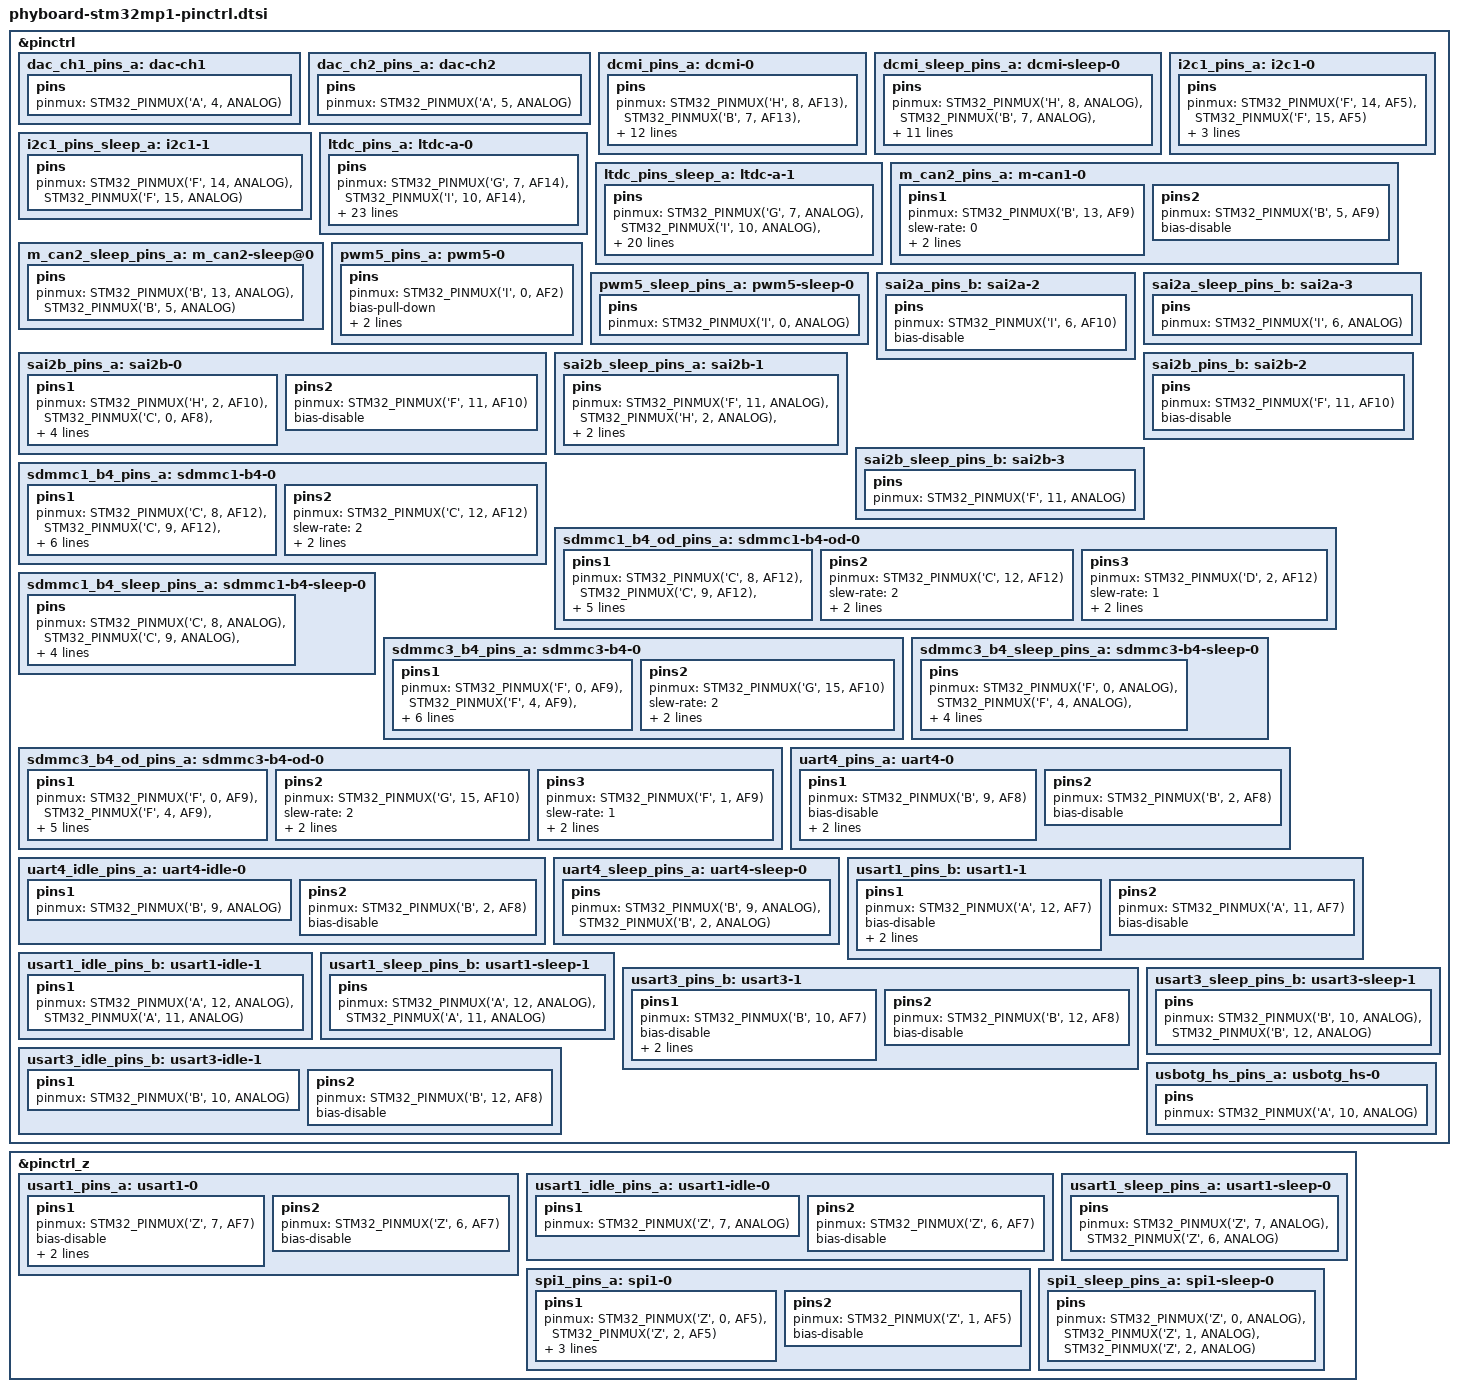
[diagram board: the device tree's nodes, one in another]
// SPDX-License-Identifier: (GPL-2.0+ OR BSD-3-Clause)
/*
 * Copyright (C) PHYTEC GmbH 2019-2020 - All Rights Reserved
 * Author: Dom VOVARD <dom.vovard@linrt.com>.
 */

#include <dt-bindings/pinctrl/stm32-pinfunc.h>

&pinctrl {

			dac_ch1_pins_a: dac-ch1 {
				pins {
					pinmux = <STM32_PINMUX('A', 4, ANALOG)>;
				};
			};

			dac_ch2_pins_a: dac-ch2 {
				pins {
					pinmux = <STM32_PINMUX('A', 5, ANALOG)>;
				};
			};

			dcmi_pins_a: dcmi-0 {
				pins {
					pinmux = <STM32_PINMUX('H', 8,  AF13)>,/* DCMI_HSYNC */
						 <STM32_PINMUX('B', 7,  AF13)>,/* DCMI_VSYNC */
						 <STM32_PINMUX('A', 6,  AF13)>,/* DCMI_PIXCLK */
						 <STM32_PINMUX('H', 9,  AF13)>,/* DCMI_D0 */
						 <STM32_PINMUX('C', 7,  AF13)>,/* DCMI_D1 */
						 <STM32_PINMUX('E', 0,  AF13)>,/* DCMI_D2 */
						 <STM32_PINMUX('E', 1,  AF13)>,/* DCMI_D3 */
						 <STM32_PINMUX('H', 14, AF13)>,/* DCMI_D4 */
						 <STM32_PINMUX('I', 4,  AF13)>,/* DCMI_D5 */
						 <STM32_PINMUX('E', 5,  AF13)>,/* DCMI_D6 */
						 <STM32_PINMUX('I', 7,  AF13)>,/* DCMI_D7 */
						 <STM32_PINMUX('I', 1,  AF13)>,/* DCMI_D8 */
						 <STM32_PINMUX('H', 7,  AF13)>;/* DCMI_D9 */
					bias-disable;
				};
			};

			dcmi_sleep_pins_a: dcmi-sleep-0 {
				pins {
					pinmux = <STM32_PINMUX('H', 8,  ANALOG)>,/* DCMI_HSYNC */
						 <STM32_PINMUX('B', 7,  ANALOG)>,/* DCMI_VSYNC */
						 <STM32_PINMUX('A', 6,  ANALOG)>,/* DCMI_PIXCLK */
						 <STM32_PINMUX('H', 9,  ANALOG)>,/* DCMI_D0 */
						 <STM32_PINMUX('C', 7,  ANALOG)>,/* DCMI_D1 */
						 <STM32_PINMUX('E', 0,  ANALOG)>,/* DCMI_D2 */
						 <STM32_PINMUX('E', 1,  ANALOG)>,/* DCMI_D3 */
						 <STM32_PINMUX('H', 14, ANALOG)>,/* DCMI_D4 */
						 <STM32_PINMUX('I', 4,  ANALOG)>,/* DCMI_D5 */
						 <STM32_PINMUX('E', 5,  ANALOG)>,/* DCMI_D6 */
						 <STM32_PINMUX('I', 7,  ANALOG)>,/* DCMI_D7 */
						 <STM32_PINMUX('I', 1,  ANALOG)>,/* DCMI_D8 */
						 <STM32_PINMUX('H', 7,  ANALOG)>;/* DCMI_D9 */
				};
			};


			i2c1_pins_a: i2c1-0 {
				pins {
					pinmux = <STM32_PINMUX('F', 14, AF5)>, /* I2C1_SCL */
						 <STM32_PINMUX('F', 15, AF5)>; /* I2C1_SDA */
					bias-disable;
					drive-open-drain;
					slew-rate = <0>;
				};
			};

			i2c1_pins_sleep_a: i2c1-1 {
				pins {
					pinmux = <STM32_PINMUX('F', 14, ANALOG)>, /* I2C1_SCL */
						 <STM32_PINMUX('F', 15, ANALOG)>; /* I2C1_SDA */
				};
			};


			ltdc_pins_a: ltdc-a-0 {
				pins {
					pinmux = <STM32_PINMUX('G', 7,  AF14)>, /* LCD_CLK */
						 <STM32_PINMUX('I', 10, AF14)>, /* LCD_HSYNC */
						 <STM32_PINMUX('I', 9,  AF14)>, /* LCD_VSYNC */
						 <STM32_PINMUX('E', 13, AF14)>, /* LCD_DE */
						 <STM32_PINMUX('C', 10, AF14)>, /* LCD_R2 */
						 <STM32_PINMUX('B', 0,   AF9)>, /* LCD_R3 */
						 <STM32_PINMUX('H', 10, AF14)>, /* LCD_R4 */
						 <STM32_PINMUX('H', 11, AF14)>, /* LCD_R5 */
						 <STM32_PINMUX('H', 12, AF14)>, /* LCD_R6 */
						 <STM32_PINMUX('E', 15, AF14)>, /* LCD_R7 */
						 <STM32_PINMUX('H', 13, AF14)>, /* LCD_G2 */
						 <STM32_PINMUX('E', 11, AF14)>, /* LCD_G3 */
						 <STM32_PINMUX('H', 15, AF14)>, /* LCD_G4 */
						 <STM32_PINMUX('H', 4,   AF9)>, /* LCD_G5 */
						 <STM32_PINMUX('I', 11,  AF9)>, /* LCD_G6 */
						 <STM32_PINMUX('I', 2,  AF14)>, /* LCD_G7 */
						 <STM32_PINMUX('G', 10, AF14)>, /* LCD_B2 */
						 <STM32_PINMUX('G', 11, AF14)>, /* LCD_B3 */
						 <STM32_PINMUX('E', 12, AF14)>, /* LCD_B4 */
						 <STM32_PINMUX('I', 5,  AF14)>, /* LCD_B5 */
						 <STM32_PINMUX('B', 8,  AF14)>, /* LCD_B6 */
						 <STM32_PINMUX('D', 8,  AF14)>; /* LCD_B7 */
					bias-disable;
					drive-push-pull;
					slew-rate = <1>;
				};
			};

			ltdc_pins_sleep_a: ltdc-a-1 {
				pins {
                                        pinmux = <STM32_PINMUX('G', 7,  ANALOG)>, /* LCD_CLK */
                                                 <STM32_PINMUX('I', 10, ANALOG)>, /* LCD_HSYNC */
                                                 <STM32_PINMUX('I', 9,  ANALOG)>, /* LCD_VSYNC */
                                                 <STM32_PINMUX('E', 13, ANALOG)>, /* LCD_DE */
                                                 <STM32_PINMUX('C', 10, ANALOG)>, /* LCD_R2 */
                                                 <STM32_PINMUX('B', 0,  ANALOG)>, /* LCD_R3 */
                                                 <STM32_PINMUX('H', 10, ANALOG)>, /* LCD_R4 */
                                                 <STM32_PINMUX('H', 11, ANALOG)>, /* LCD_R5 */
                                                 <STM32_PINMUX('H', 12, ANALOG)>, /* LCD_R6 */
                                                 <STM32_PINMUX('E', 15, ANALOG)>, /* LCD_R7 */
                                                 <STM32_PINMUX('H', 13, ANALOG)>, /* LCD_G2 */
                                                 <STM32_PINMUX('E', 11, ANALOG)>, /* LCD_G3 */
                                                 <STM32_PINMUX('H', 15, ANALOG)>, /* LCD_G4 */
                                                 <STM32_PINMUX('H', 4,  ANALOG)>, /* LCD_G5 */
                                                 <STM32_PINMUX('I', 11, ANALOG)>, /* LCD_G6 */
                                                 <STM32_PINMUX('I', 2,  ANALOG)>, /* LCD_G7 */
                                                 <STM32_PINMUX('G', 10, ANALOG)>, /* LCD_B2 */
                                                 <STM32_PINMUX('G', 11, ANALOG)>, /* LCD_B3 */
                                                 <STM32_PINMUX('E', 12, ANALOG)>, /* LCD_B4 */
                                                 <STM32_PINMUX('I', 5,  ANALOG)>, /* LCD_B5 */
                                                 <STM32_PINMUX('B', 8,  ANALOG)>, /* LCD_B6 */
                                                 <STM32_PINMUX('D', 8,  ANALOG)>; /* LCD_B7 */
                                };
			};


			m_can2_pins_a: m-can1-0 {
				pins1 {
					pinmux = <STM32_PINMUX('B', 13, AF9)>; /* CAN2_TX */
					slew-rate = <0>;
					drive-push-pull;
					bias-disable;
				};
				pins2 {
					pinmux = <STM32_PINMUX('B', 5, AF9)>; /* CAN2_RX */
                                                bias-disable;
				};
			};

			m_can2_sleep_pins_a: m_can2-sleep@0 {
				pins {
					pinmux = <STM32_PINMUX('B', 13, ANALOG)>, /* CAN2_TX */
						 <STM32_PINMUX('B', 5, ANALOG)>; /* CAN2_RX */
				};
			};


			pwm5_pins_a: pwm5-0 {
				pins {
					pinmux = <STM32_PINMUX('I', 0, AF2)>; /* TIM5_CH4 */
					bias-pull-down;
					drive-push-pull;
					slew-rate = <0>;
				};
			};

			pwm5_sleep_pins_a: pwm5-sleep-0 {
				pins {
					pinmux = <STM32_PINMUX('I', 0, ANALOG)>; /* TIM5_CH4 */
				};
			};


                        sai2a_pins_b: sai2a-2 {
                                pins {
                                        pinmux = <STM32_PINMUX('I', 6, AF10)>; /* SAI2_SD_A */
                                        bias-disable;
                                };
                        };

                        sai2a_sleep_pins_b: sai2a-3 {
                                pins {
                                        pinmux = <STM32_PINMUX('I', 6, ANALOG)>; /* SAI2_SD_A */
                                };
                        };

			sai2b_pins_a: sai2b-0 {
				pins1 {
					pinmux = <STM32_PINMUX('H', 2, AF10)>, /* SAI2_SCK_B */
						 <STM32_PINMUX('C', 0, AF8)>, /* SAI2_FS_B */
						 <STM32_PINMUX('H', 3, AF10)>; /* SAI2_MCLK_B */
					slew-rate = <0>;
					drive-push-pull;
					bias-disable;
				};
				pins2 {
					pinmux = <STM32_PINMUX('F', 11, AF10)>; /* SAI2_SD_B */
					bias-disable;
				};
			};

			sai2b_sleep_pins_a: sai2b-1 {
				pins {
					pinmux = <STM32_PINMUX('F', 11, ANALOG)>, /* SAI2_SD_B */
						 <STM32_PINMUX('H', 2, ANALOG)>, /* SAI2_SCK_B */
						 <STM32_PINMUX('C', 0, ANALOG)>, /* SAI2_FS_B */
						 <STM32_PINMUX('H', 3, ANALOG)>; /* SAI2_MCLK_B */
				};
			};

			sai2b_pins_b: sai2b-2 {
				pins {
					pinmux = <STM32_PINMUX('F', 11, AF10)>; /* SAI2_SD_B */
					bias-disable;
				};
			};

			sai2b_sleep_pins_b: sai2b-3 {
				pins {
					pinmux = <STM32_PINMUX('F', 11, ANALOG)>; /* SAI2_SD_B */
				};
			};


			sdmmc1_b4_pins_a: sdmmc1-b4-0 {
				pins1 {
					pinmux = <STM32_PINMUX('C', 8, AF12)>, /* SDMMC1_D0 */
						 <STM32_PINMUX('C', 9, AF12)>, /* SDMMC1_D1 */
						 <STM32_PINMUX('E', 6, AF8)>, /* SDMMC1_D2 */
						 <STM32_PINMUX('C', 11, AF12)>, /* SDMMC1_D3 */
						 <STM32_PINMUX('D', 2, AF12)>; /* SDMMC1_CMD */
					slew-rate = <1>;
					drive-push-pull;
					bias-disable;
				};
				pins2 {
					pinmux = <STM32_PINMUX('C', 12, AF12)>; /* SDMMC1_CK */
					slew-rate = <2>;
					drive-push-pull;
					bias-disable;
				};
			};

			sdmmc1_b4_od_pins_a: sdmmc1-b4-od-0 {
				pins1 {
					pinmux = <STM32_PINMUX('C', 8, AF12)>, /* SDMMC1_D0 */
						 <STM32_PINMUX('C', 9, AF12)>, /* SDMMC1_D1 */
						 <STM32_PINMUX('E', 6, AF8)>, /* SDMMC1_D2 */
						 <STM32_PINMUX('C', 11, AF12)>; /* SDMMC1_D3 */
					slew-rate = <1>;
					drive-push-pull;
					bias-disable;
				};
				pins2 {
					pinmux = <STM32_PINMUX('C', 12, AF12)>; /* SDMMC1_CK */
					slew-rate = <2>;
					drive-push-pull;
					bias-disable;
				};
				pins3 {
					pinmux = <STM32_PINMUX('D', 2, AF12)>; /* SDMMC1_CMD */
					slew-rate = <1>;
					drive-open-drain;
					bias-disable;
				};
			};

			sdmmc1_b4_sleep_pins_a: sdmmc1-b4-sleep-0 {
				pins {
					pinmux = <STM32_PINMUX('C', 8, ANALOG)>, /* SDMMC1_D0 */
						 <STM32_PINMUX('C', 9, ANALOG)>, /* SDMMC1_D1 */
						 <STM32_PINMUX('E', 6, ANALOG)>, /* SDMMC1_D2 */
						 <STM32_PINMUX('C', 11, ANALOG)>, /* SDMMC1_D3 */
						 <STM32_PINMUX('C', 12, ANALOG)>, /* SDMMC1_CK */
						 <STM32_PINMUX('D', 2, ANALOG)>; /* SDMMC1_CMD */
				};
			};

			sdmmc3_b4_pins_a: sdmmc3-b4-0 {
				pins1 {
					pinmux = <STM32_PINMUX('F', 0, AF9)>, /* SDMMC3_D0 */
						 <STM32_PINMUX('F', 4, AF9)>, /* SDMMC3_D1 */
						 <STM32_PINMUX('F', 5, AF9)>, /* SDMMC3_D2 */
						 <STM32_PINMUX('D', 7, AF10)>, /* SDMMC3_D3 */
						 <STM32_PINMUX('F', 1, AF9)>; /* SDMMC3_CMD */
					slew-rate = <1>;
					drive-push-pull;
					bias-pull-up;
				};
				pins2 {
					pinmux = <STM32_PINMUX('G', 15, AF10)>; /* SDMMC3_CK */
					slew-rate = <2>;
					drive-push-pull;
					bias-pull-up;
				};
			};

			sdmmc3_b4_od_pins_a: sdmmc3-b4-od-0 {
				pins1 {
					pinmux = <STM32_PINMUX('F', 0, AF9)>, /* SDMMC3_D0 */
						 <STM32_PINMUX('F', 4, AF9)>, /* SDMMC3_D1 */
						 <STM32_PINMUX('F', 5, AF9)>, /* SDMMC3_D2 */
						 <STM32_PINMUX('D', 7, AF10)>; /* SDMMC3_D3 */
					slew-rate = <1>;
					drive-push-pull;
					bias-pull-up;
				};
				pins2 {
					pinmux = <STM32_PINMUX('G', 15, AF10)>; /* SDMMC3_CK */
					slew-rate = <2>;
					drive-push-pull;
					bias-pull-up;
				};
				pins3 {
					pinmux = <STM32_PINMUX('F', 1, AF9)>; /* SDMMC2_CMD */
					slew-rate = <1>;
					drive-open-drain;
					bias-pull-up;
				};
			};

			sdmmc3_b4_sleep_pins_a: sdmmc3-b4-sleep-0 {
				pins {
					pinmux = <STM32_PINMUX('F', 0, ANALOG)>, /* SDMMC3_D0 */
						 <STM32_PINMUX('F', 4, ANALOG)>, /* SDMMC3_D1 */
						 <STM32_PINMUX('F', 5, ANALOG)>, /* SDMMC3_D2 */
						 <STM32_PINMUX('D', 7, ANALOG)>, /* SDMMC3_D3 */
						 <STM32_PINMUX('G', 15, ANALOG)>, /* SDMMC3_CK */
						 <STM32_PINMUX('F', 1, ANALOG)>; /* SDMMC3_CMD */
				};
			};


			uart4_pins_a: uart4-0 {
				pins1 {
					pinmux = <STM32_PINMUX('B', 9, AF8)>; /* UART4_TX */
					bias-disable;
					drive-push-pull;
					slew-rate = <0>;
				};
				pins2 {
					pinmux = <STM32_PINMUX('B', 2, AF8)>; /* UART4_RX */
					bias-disable;
				};
			};

			uart4_idle_pins_a: uart4-idle-0 {
				pins1 {
					pinmux = <STM32_PINMUX('B', 9, ANALOG)>; /* UART4_TX */
				};
				pins2 {
					pinmux = <STM32_PINMUX('B', 2, AF8)>; /* UART4_RX */
					bias-disable;
				};
			};

			uart4_sleep_pins_a: uart4-sleep-0 {
				pins {
					pinmux = <STM32_PINMUX('B', 9, ANALOG)>, /* UART4_TX */
						 <STM32_PINMUX('B', 2, ANALOG)>; /* UART4_RX */
				};
			};

                       usart1_pins_b: usart1-1 {
                               pins1 {
                                       pinmux = <STM32_PINMUX('A', 12, AF7)>; /* USART1_RTS */
                                       bias-disable;
                                       drive-push-pull;
                                       slew-rate = <0>;
                               };
                               pins2 {
                                       pinmux = <STM32_PINMUX('A', 11, AF7)>; /* USART1_CTS_NSS */
                                       bias-disable;
                               };
                       };

                       usart1_idle_pins_b: usart1-idle-1 {
                               pins1 {
                                       pinmux = <STM32_PINMUX('A', 12, ANALOG)>, /* USART1_RTS */
                                                <STM32_PINMUX('A', 11, ANALOG)>; /* USART1_CTS_NSS */
                               };
                       };

                       usart1_sleep_pins_b: usart1-sleep-1 {
                               pins {
                                       pinmux = <STM32_PINMUX('A', 12, ANALOG)>, /* USART1_RTS */
                                                <STM32_PINMUX('A', 11, ANALOG)>; /* USART1_CTS_NSS */
                               };
                       };

			usart3_pins_b: usart3-1 {
				pins1 {
					pinmux = <STM32_PINMUX('B', 10, AF7)>; /* USART3_TX */
					bias-disable;
					drive-push-pull;
					slew-rate = <0>;
				};
				pins2 {
					pinmux = <STM32_PINMUX('B', 12, AF8)>; /* USART3_RX */
					bias-disable;
				};
			};

			usart3_idle_pins_b: usart3-idle-1 {
				pins1 {
					pinmux = <STM32_PINMUX('B', 10, ANALOG)>; /* USART3_TX */
				};
				pins2 {
					pinmux = <STM32_PINMUX('B', 12, AF8)>; /* USART3_RX */
					bias-disable;
				};
			};

			usart3_sleep_pins_b: usart3-sleep-1 {
				pins {
					pinmux = <STM32_PINMUX('B', 10, ANALOG)>, /* USART3_TX */
						 <STM32_PINMUX('B', 12, ANALOG)>; /* USART3_RX */
				};
			};

			usbotg_hs_pins_a: usbotg_hs-0 {
				pins {
					pinmux = <STM32_PINMUX('A', 10, ANALOG)>; /* OTG_ID */
				};
			};
};

&pinctrl_z {

	usart1_pins_a: usart1-0 {
		pins1 {
			pinmux = <STM32_PINMUX('Z', 7, AF7)>; /* USART1_TX */
			bias-disable;
			drive-push-pull;
			slew-rate = <0>;
		};
		pins2 {
			pinmux = <STM32_PINMUX('Z', 6, AF7)>; /* USART1_RX */
			bias-disable;
		};
	};

	usart1_idle_pins_a: usart1-idle-0 {
		pins1 {
			pinmux = <STM32_PINMUX('Z', 7, ANALOG)>; /* USART1_TX */
		};
		pins2 {
			pinmux = <STM32_PINMUX('Z', 6, AF7)>; /* USART1_RX */
			bias-disable;
		};
	};

	usart1_sleep_pins_a: usart1-sleep-0 {
		pins {
			pinmux = <STM32_PINMUX('Z', 7, ANALOG)>, /* USART1_TX */
				 <STM32_PINMUX('Z', 6, ANALOG)>; /* USART1_RX */
		};
	};

        spi1_pins_a: spi1-0 {
                pins1 {
                        pinmux = <STM32_PINMUX('Z', 0, AF5)>, /* SPI1_SCK */
                                <STM32_PINMUX('Z', 2, AF5)>; /* SPI1_MOSI */
                        bias-disable;
                        drive-push-pull;
                        slew-rate = <1>;
                };
                pins2 {
                        pinmux = <STM32_PINMUX('Z', 1, AF5)>; /* SPI1_MISO */
                        bias-disable;
                };
        };

        spi1_sleep_pins_a: spi1-sleep-0 {
                pins {
                        pinmux = <STM32_PINMUX('Z', 0, ANALOG)>, /* SPI1_SCK */
                                 <STM32_PINMUX('Z', 1, ANALOG)>, /* SPI1_MISO */
                                 <STM32_PINMUX('Z', 2, ANALOG)>; /* SPI1_MOSI */
                };
        };
};
